# PN73xxAU register map
File version: 2
CPU: CM0 r0p0, little endian, no MPU, no FPU, 2 interrupt priority bits
Registers are 32-bit, read-write, reset 0x0 unless marked. A register's access mark holds for its fields unless they carry their own. Offsets are from the block's base; [hi:lo] are bit positions.

## EECTRL — EEPROM and Flash Controller
Base 0x00200000
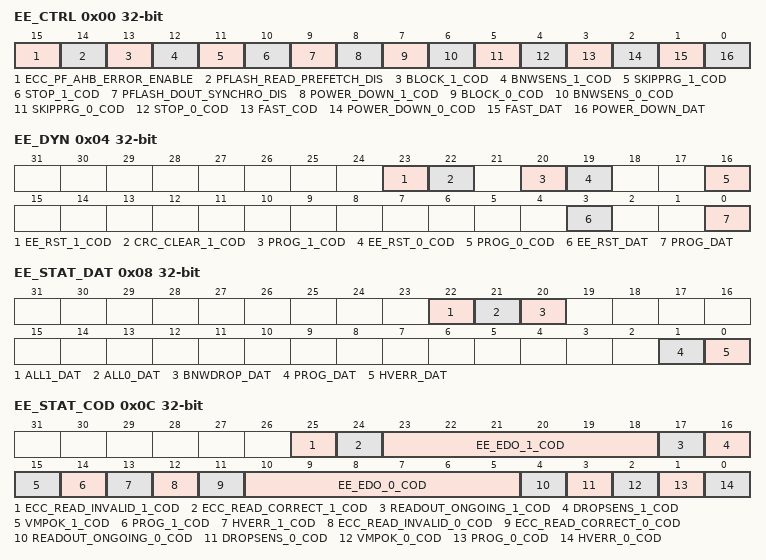
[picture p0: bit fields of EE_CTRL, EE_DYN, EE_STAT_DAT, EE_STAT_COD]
0x00 EE_CTRL — EECTRL General Control Register (RW)
  [15] ECC_PF_AHB_ERROR_ENABLE — When 1 enables the AHB error generation when PFLASH read data cannot be corrected by the ECC mechanism
  [14] PFLASH_READ_PREFETCH_DIS — 1 disables the PAGEFLASH read prefetching feature
  [13] BLOCK_1_COD — Block Mode for PAGEFLASH_1
  [12] BNWSENS_1_COD — Voltage Drop Sensor Enable for PAGEFLASH_1
  [11] SKIPPRG_1_COD — Skip Program if erase fails for PAGEFLASH_1
  [10] STOP_1_COD — Stop Ramp-Up at Low Power for PAGEFLASH_1
  [9] PFLASH_DOUT_SYNCHRO_DIS — Reserved
  [8] POWER_DOWN_1_COD — Power Down for PAGEFLASH_1 Memory
  [7] BLOCK_0_COD — Block Mode for PAGEFLASH_0
  [6] BNWSENS_0_COD — When 0 output PAGEFLASH data is synchronized with the system clock to ensure that following ECC calculation is made on stable data (recommanded by the memories providers) It is automatically set to 1 if FAST_COD = 1
  [5] SKIPPRG_0_COD — Skip Program if erase fails for PAGEFLASH_0
  [4] STOP_0_COD — Stop Ramp-Up at Low Power for PAGEFLASH_0
  [3] FAST_COD — Fast Access Mode for both PAGEFLASH_0 and PAGEFLASH_1
  [2] POWER_DOWN_0_COD — Power Down for PAGEFLASH_0 Memory
  [1] FAST_DAT — Fast EEPROM Access Mode
  [0] POWER_DOWN_DAT — Power Down for EEPROM Memory
0x04 EE_DYN wo — EECTRL Dynamic Control Register (WO)
  [23] EE_RST_1_COD — Resets the PAGEFLASH_1 Controller
  [22] CRC_CLEAR_1_COD — CRC Clear Function for PAGEFLASH_1 fulldump Readout
  [20] PROG_1_COD — Starts Programming PAGEFLASH_1 Row from the Page Register
  [19] EE_RST_0_COD — Resets the PAGEFLASH_0 Controller
  [16] PROG_0_COD — Starts Programming PAGEFLASH_0 Row from the Page Register
  [3] EE_RST_DAT — Resets the EEPROM Controller
  [0] PROG_DAT — Starts Programming EEPROM Row from the Page Register
0x08 EE_STAT_DAT ro — EECTRL Status Register (RO)
  [22] ALL1_DAT — SFI (Single Fault Injection) High Detection Flag for the EEPROM
  [21] ALL0_DAT — SFI (Single Fault Injection) Low Detection Flag for the EEPROM
  [20] BNWDROP_DAT — BNW Sensor Signal for EEPROM
  [1] PROG_DAT — Indicator if Programming is ongoing for the EEPROM
  [0] HVERR_DAT — HV Error Signal for EEPROM
0x0C EE_STAT_COD ro — EECTRL Status Register (RO)
  [25] ECC_READ_INVALID_1_COD — 1 means that read access cannot be corrected. There are more than one bit error
  [24] ECC_READ_CORRECT_1_COD — 0 means that ther is at teast one bit error, check the ECC_READ_INVALID_1_COD to confirm if it has been corrected or not 1 mean that not bit error occured
  [23:18] EE_EDO_1_COD — EDO Parity Lines for the PAGEFLASH_1 32-bit data
  [17] READOUT_ONGOING_1_COD — Full or Partial Dump Readout ongoing for the entire PAGEFLASH_1
  [16] DROPSENS_1_COD — Drop Sensor Output Signal for PAGEFLASH_1
  [15] VMPOK_1_COD — Margin Voltage Flag for PAGEFLASH_1
  [14] PROG_1_COD — Indicator if Programming is ongoing for the PAGEFLASH_1
  [13] HVERR_1_COD — HV Error Signal for PAGEFLASH_1
  [12] ECC_READ_INVALID_0_COD — 1 means that read access cannot be corrected. There are more than one bit error
  [11] ECC_READ_CORRECT_0_COD — 0 means that ther is at teast one bit error, check the ECC_READ_INVALID_0_COD to confirm if it has been corrected or not 1 mean that not bit error occured
  [10:5] EE_EDO_0_COD — EDO Parity Lines for the PAGEFLASH_0 32-bit data
  [4] READOUT_ONGOING_0_COD — Full or Partial Dump Readout ongoing for the entire PAGEFLASH_0
  [3] DROPSENS_0_COD — Drop Sensor Output Signal for PAGEFLASH_0
  [2] VMPOK_0_COD — Margin Voltage Flag for PAGEFLASH_0
  [1] PROG_0_COD — Indicator if Programming is ongoing for the PAGEFLASH_0
  [0] HVERR_0_COD — HV Error Signal for PAGEFLASH_0
0x44 EE_ECC_PF_AHB_ERROR_ADDR — PFLASH ECC Error Address
  [17:0] ECC_PF_AHB_ERROR_ADDR ro
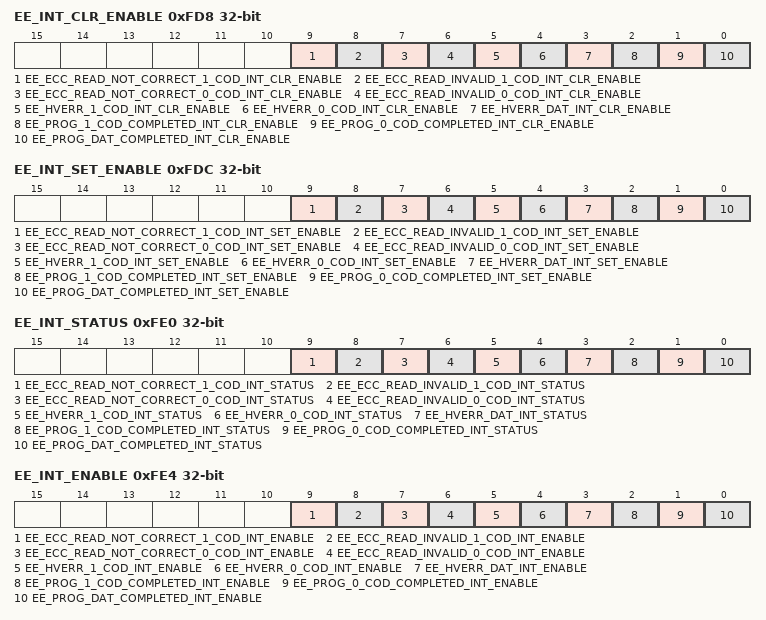
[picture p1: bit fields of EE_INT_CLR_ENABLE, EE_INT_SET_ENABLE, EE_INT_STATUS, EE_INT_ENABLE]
0xFD8 EE_INT_CLR_ENABLE wo — PFLASH ECC Error Address
  [9] EE_ECC_READ_NOT_CORRECT_1_COD_INT_CLR_ENABLE — PFLASH_1 Not Correct ECC Read Interrupt Clear Enable Command
  [8] EE_ECC_READ_INVALID_1_COD_INT_CLR_ENABLE — PFLASH_1 Invalid ECC Read Interrupt Clear Enable Command
  [7] EE_ECC_READ_NOT_CORRECT_0_COD_INT_CLR_ENABLE — PFLASH_0 Not Correct ECC Read Interrupt Clear Enable Command
  [6] EE_ECC_READ_INVALID_0_COD_INT_CLR_ENABLE — PFLASH_0 Invalid ECC Read Interrupt Clear Enable Command
  [5] EE_HVERR_1_COD_INT_CLR_ENABLE — PFLASH_1 High Voltage Error Interrupt Clear Enable Command
  [4] EE_HVERR_0_COD_INT_CLR_ENABLE — PFLASH_0 High Voltage Error Interrupt Clear Enable Command
  [3] EE_HVERR_DAT_INT_CLR_ENABLE — EEPROM High Voltage Error Interrupt Clear Enable Command
  [2] EE_PROG_1_COD_COMPLETED_INT_CLR_ENABLE — PFLASH_1 Programming Completed Interrupt Clear Enable Command
  [1] EE_PROG_0_COD_COMPLETED_INT_CLR_ENABLE — PFLASH_0 Programming Completed Interrupt Clear Enable Command
  [0] EE_PROG_DAT_COMPLETED_INT_CLR_ENABLE — EEPROM Programming Completed Interrupt Clear Enable Command
0xFDC EE_INT_SET_ENABLE wo — PFLASH ECC Error Address
  [9] EE_ECC_READ_NOT_CORRECT_1_COD_INT_SET_ENABLE — PFLASH_1 Not Correct ECC Read Interrupt Set Enable Command
  [8] EE_ECC_READ_INVALID_1_COD_INT_SET_ENABLE — PFLASH_1 Invalid ECC Read Interrupt Set Enable Command
  [7] EE_ECC_READ_NOT_CORRECT_0_COD_INT_SET_ENABLE — PFLASH_0 Not Correct ECC Read Interrupt Set Enable Command
  [6] EE_ECC_READ_INVALID_0_COD_INT_SET_ENABLE — PFLASH_0 Invalid ECC Read Interrupt Set Enable Command
  [5] EE_HVERR_1_COD_INT_SET_ENABLE — PFLASH_1 High Voltage Error Interrupt Set Enable Command
  [4] EE_HVERR_0_COD_INT_SET_ENABLE — PFLASH_0 High Voltage Error Interrupt Set Enable Command
  [3] EE_HVERR_DAT_INT_SET_ENABLE — EEPROM High Voltage Error Interrupt Set Enable Command
  [2] EE_PROG_1_COD_COMPLETED_INT_SET_ENABLE — PFLASH_1 Programming Completed Interrupt Set Enable Command
  [1] EE_PROG_0_COD_COMPLETED_INT_SET_ENABLE — PFLASH_0 Programming Completed Interrupt Set Enable Command
  [0] EE_PROG_DAT_COMPLETED_INT_SET_ENABLE — EEPROM Programming Completed Interrupt Set Enable Command
0xFE0 EE_INT_STATUS ro — PFLASH ECC Error Address
  [9] EE_ECC_READ_NOT_CORRECT_1_COD_INT_STATUS — PFLASH_1 Not Correct ECC Read Interrupt Status Variable
  [8] EE_ECC_READ_INVALID_1_COD_INT_STATUS — PFLASH_1 Invalid ECC Read Interrupt Status Variable
  [7] EE_ECC_READ_NOT_CORRECT_0_COD_INT_STATUS — PFLASH_0 Not Correct ECC Read Interrupt Status Variable
  [6] EE_ECC_READ_INVALID_0_COD_INT_STATUS — PFLASH_0 Invalid ECC Read Interrupt Status Variable
  [5] EE_HVERR_1_COD_INT_STATUS — PFLASH_1 High Voltage Error Interrupt Status Variable
  [4] EE_HVERR_0_COD_INT_STATUS — PFLASH_0 High Voltage Error Interrupt Status Variable
  [3] EE_HVERR_DAT_INT_STATUS — EEPROM High Voltage Error Interrupt Status Variable
  [2] EE_PROG_1_COD_COMPLETED_INT_STATUS — PFLASH_1 Programming Completed Interrupt Status Variable
  [1] EE_PROG_0_COD_COMPLETED_INT_STATUS — PFLASH_0 Programming Completed Interrupt Status Variable
  [0] EE_PROG_DAT_COMPLETED_INT_STATUS — EEPROM Programming Completed Interrupt Status Variable
0xFE4 EE_INT_ENABLE ro — PFLASH ECC Error Address
  [9] EE_ECC_READ_NOT_CORRECT_1_COD_INT_ENABLE — PFLASH_1 Not Correct ECC Read Interrupt Enable Variable
  [8] EE_ECC_READ_INVALID_1_COD_INT_ENABLE — PFLASH_1 Invalid ECC Read Interrupt Enable Variable
  [7] EE_ECC_READ_NOT_CORRECT_0_COD_INT_ENABLE — PFLASH_0 Not Correct ECC Read Interrupt Enable Variable
  [6] EE_ECC_READ_INVALID_0_COD_INT_ENABLE — PFLASH_0 Invalid ECC Read Interrupt Enable Variable
  [5] EE_HVERR_1_COD_INT_ENABLE — PFLASH_1 High Voltage Error Interrupt Enable Variable
  [4] EE_HVERR_0_COD_INT_ENABLE — PFLASH_0 High Voltage Error Interrupt Enable Variable
  [3] EE_HVERR_DAT_INT_ENABLE — EEPROM High Voltage Error Interrupt Enable Variable
  [2] EE_PROG_1_COD_COMPLETED_INT_ENABLE — PFLASH_1 Programming Completed Interrupt Enable Variable
  [1] EE_PROG_0_COD_COMPLETED_INT_ENABLE — PFLASH_0 Programming Completed Interrupt Enable Variable
  [0] EE_PROG_DAT_COMPLETED_INT_ENABLE — EEPROM Programming Completed Interrupt Enable Variable
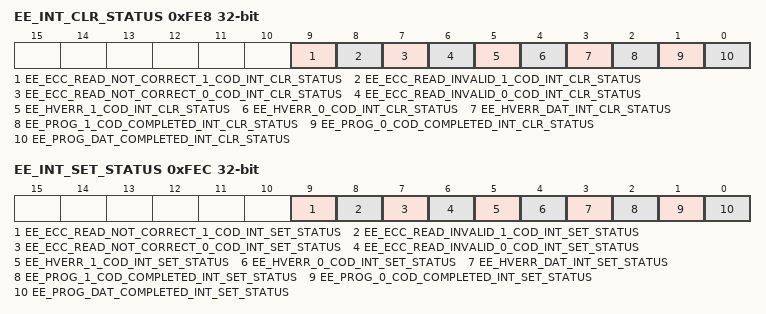
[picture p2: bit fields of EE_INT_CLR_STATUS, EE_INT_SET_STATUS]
0xFE8 EE_INT_CLR_STATUS wo — PFLASH ECC Error Address
  [9] EE_ECC_READ_NOT_CORRECT_1_COD_INT_CLR_STATUS — PFLASH_1 Not Correct ECC Read Interrupt Clear Status Command
  [8] EE_ECC_READ_INVALID_1_COD_INT_CLR_STATUS — PFLASH_1 Invalid ECC Read Interrupt Clear Status Command
  [7] EE_ECC_READ_NOT_CORRECT_0_COD_INT_CLR_STATUS — PFLASH_0 Not Correct ECC Read Interrupt Clear Status Command
  [6] EE_ECC_READ_INVALID_0_COD_INT_CLR_STATUS — PFLASH_0 Invalid ECC Read Interrupt Clear Status Command
  [5] EE_HVERR_1_COD_INT_CLR_STATUS — PFLASH_1 High Voltage Error Interrupt Clear Status Command
  [4] EE_HVERR_0_COD_INT_CLR_STATUS — PFLASH_0 High Voltage Error Interrupt Clear Status Command
  [3] EE_HVERR_DAT_INT_CLR_STATUS — EEPROM High Voltage Error Interrupt Clear Status Command
  [2] EE_PROG_1_COD_COMPLETED_INT_CLR_STATUS — PFLASH_1 Programming Completed Interrupt Clear Status Command
  [1] EE_PROG_0_COD_COMPLETED_INT_CLR_STATUS — PFLASH_0 Programming Completed Interrupt Clear Status Command
  [0] EE_PROG_DAT_COMPLETED_INT_CLR_STATUS — EEPROM Programming Completed Interrupt Clear Status Command
0xFEC EE_INT_SET_STATUS wo — PFLASH ECC Error Address
  [9] EE_ECC_READ_NOT_CORRECT_1_COD_INT_SET_STATUS — PFLASH_1 Not Correct ECC Read Interrupt Set Status Command
  [8] EE_ECC_READ_INVALID_1_COD_INT_SET_STATUS — PFLASH_1 Invalid ECC Read Interrupt Set Status Command
  [7] EE_ECC_READ_NOT_CORRECT_0_COD_INT_SET_STATUS — PFLASH_0 Not Correct ECC Read Interrupt Set Status Command
  [6] EE_ECC_READ_INVALID_0_COD_INT_SET_STATUS — PFLASH_0 Invalid ECC Read Interrupt Set Status Command
  [5] EE_HVERR_1_COD_INT_SET_STATUS — PFLASH_1 High Voltage Error Interrupt Set Status Command
  [4] EE_HVERR_0_COD_INT_SET_STATUS — PFLASH_0 High Voltage Error Interrupt Set Status Command
  [3] EE_HVERR_DAT_INT_SET_STATUS — EEPROM High Voltage Error Interrupt Set Status Command
  [2] EE_PROG_1_COD_COMPLETED_INT_SET_STATUS — PFLASH_1 Programming Completed Interrupt Set Status Command
  [1] EE_PROG_0_COD_COMPLETED_INT_SET_STATUS — PFLASH_0 Programming Completed Interrupt Set Status Command
  [0] EE_PROG_DAT_COMPLETED_INT_SET_STATUS — EEPROM Programming Completed Interrupt Set Status Command
